# LPC18xx register map
File version: 18
Registers are 32-bit, read-write, reset 0x0 unless marked. A register's access mark holds for its fields unless they carry their own. Offsets are from the block's base; [hi:lo] are bit positions; {n}, {i} and the like mark numbered series; 'fields as' and 'values as' point back to an identical list.

## MCPWM — Product name title=UM10430 Chapter title=LPC18xx Motor Control PWM (MOTOCONPWM) Modification date=1/14/2011 Major revision=0 Minor revision=7
Base 0x400A0000
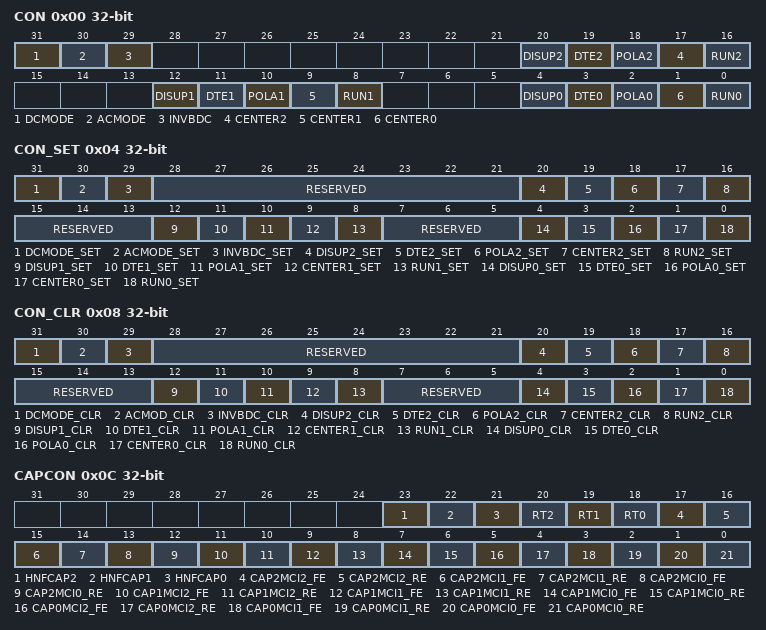
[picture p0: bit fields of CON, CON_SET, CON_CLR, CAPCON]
0x00 CON ro — PWM Control read address
  [31] DCMODE — 3-phase DC mode select (see Section 24.8.6).
    0=3_PHASE_DC_MODE_OFF (3-phase DC mode off: PWM channels are independent (unless bit ACMODE = 1)); 1=3_PHASE_DC_MODE_ON_ (3-phase DC mode on: The internal MCOA0 output is routed through the CP register (i.e. a mask) register to all six PWM outputs.)
  [30] ACMODE — 3-phase AC mode select (see Section 24.8.7).
    0=3_PHASE_AC_MODE_OFF (3-phase AC-mode off: Each PWM channel uses its own timer-counter and period register.); 1=3_PHASE_AC_MODE_ON_ (3-phase AC-mode on: All PWM channels use the timer-counter and period register of channel 0.)
  [29] INVBDC — Controls the polarity of the MCOB outputs for all 3 channels. This bit is typically set to 1 only in 3-phase DC mode.
    0=OPPOSITE (The MCOB outputs have opposite polarity from the MCOA outputs (aside from dead time).); 1=SAME (The MCOB outputs have the same basic polarity as the MCOA outputs. (see Section 24.8.6))
  [20] DISUP2 — Enable/disable updates of functional registers for channel 2 (see Section 24.8.2).
    0=UPDATE (Functional registers are updated from the write registers at the end of each PWM cycle.); 1=NOUPDATE (Functional registers remain the same as long as the timer is running.)
  [19] DTE2 — Controls the dead-time feature for channel 1.
    0=DEAD_TIME_DISABLED_; 1=DEAD_TIME_ENABLED_
  [18] POLA2 — Selects polarity of the MCOA2 and MCOB2 pins.
    0=PASSIVE_STATE_IS_LOW (Passive state is LOW, active state is HIGH.); 1=PASSIVE_STATE_IS_HIG (Passive state is HIGH, active state is LOW.)
  [17] CENTER2 — Edge/center aligned operation for channel 2.
    0=EDGE_ALIGNED_; 1=CENTER_ALIGNED_
  [16] RUN2 — Stops/starts timer channel 2.
    0=STOP_; 1=RUN_
  [12] DISUP1 — Enable/disable updates of functional registers for channel 1 (see Section 24.8.2).
    values as DISUP2
  [11] DTE1 — Controls the dead-time feature for channel 1.
    0=DEAD_TIME_DISABLED_; 1=DEAD_TIME_ENABLED_
  [10] POLA1 — Selects polarity of the MCOA1 and MCOB1 pins.
    values as POLA2
  [9] CENTER1 — Edge/center aligned operation for channel 1.
    0=EDGE_ALIGNED_; 1=CENTER_ALIGNED_
  [8] RUN1 — Stops/starts timer channel 1.
    0=STOP_; 1=RUN_
  [4] DISUP0 — Enable/disable updates of functional registers for channel 0 (see Section 24.8.2).
    values as DISUP2
  [3] DTE0 — Controls the dead-time feature for channel 0.
    0=DEAD_TIME_DISABLED_; 1=DEAD_TIME_ENABLED_
  [2] POLA0 — Selects polarity of the MCOA0 and MCOB0 pins.
    values as POLA2
  [1] CENTER0 — Edge/center aligned operation for channel 0.
    0=EDGE_ALIGNED_; 1=CENTER_ALIGNED_
  [0] RUN0 — Stops/starts timer channel 0.
    0=STOP_; 1=RUN_
0x04 CON_SET wo reset not defined — PWM Control set address
  [31] DCMODE_SET — Writing a one sets the corresponding bit in the CON register.
  [30] ACMODE_SET — Writing a one sets the corresponding bit in the CON register.
  [29] INVBDC_SET — Writing a one sets the corresponding bit in the CON register.
  [28:21] RESERVED — Writing a one sets the corresponding bit in the CON register.
  [20] DISUP2_SET — Writing a one sets the corresponding bit in the CON register.
  [19] DTE2_SET — Writing a one sets the corresponding bit in the CON register.
  [18] POLA2_SET — Writing a one sets the corresponding bit in the CON register.
  [17] CENTER2_SET — Writing a one sets the corresponding bit in the CON register.
  [16] RUN2_SET — Writing a one sets the corresponding bit in the CON register.
  [15:13] RESERVED — Writing a one sets the corresponding bit in the CON register.
  [12] DISUP1_SET — Writing a one sets the corresponding bit in the CON register.
  [11] DTE1_SET — Writing a one sets the corresponding bit in the CON register.
  [10] POLA1_SET — Writing a one sets the corresponding bit in the CON register.
  [9] CENTER1_SET — Writing a one sets the corresponding bit in the CON register.
  [8] RUN1_SET — Writing a one sets the corresponding bit in the CON register.
  [7:5] RESERVED — Writing a one sets the corresponding bit in the CON register.
  [4] DISUP0_SET — Writing a one sets the corresponding bit in the CON register.
  [3] DTE0_SET — Writing a one sets the corresponding bit in the CON register.
  [2] POLA0_SET — Writing a one sets the corresponding bit in the CON register.
  [1] CENTER0_SET — Writing a one sets the corresponding bit in the CON register.
  [0] RUN0_SET — Writing a one sets the corresponding bit in the CON register.
0x08 CON_CLR wo reset not defined — PWM Control clear address
  [31] DCMODE_CLR — Writing a one clears the corresponding bit in the CON register.
  [30] ACMOD_CLR — Writing a one clears the corresponding bit in the CON register.
  [29] INVBDC_CLR — Writing a one clears the corresponding bit in the CON register.
  [28:21] RESERVED — Writing a one clears the corresponding bit in the CON register.
  [20] DISUP2_CLR — Writing a one clears the corresponding bit in the CON register.
  [19] DTE2_CLR — Writing a one clears the corresponding bit in the CON register.
  [18] POLA2_CLR — Writing a one clears the corresponding bit in the CON register.
  [17] CENTER2_CLR — Writing a one clears the corresponding bit in the CON register.
  [16] RUN2_CLR — Writing a one clears the corresponding bit in the CON register.
  [15:13] RESERVED — Writing a one clears the corresponding bit in the CON register.
  [12] DISUP1_CLR — Writing a one clears the corresponding bit in the CON register.
  [11] DTE1_CLR — Writing a one clears the corresponding bit in the CON register.
  [10] POLA1_CLR — Writing a one clears the corresponding bit in the CON register.
  [9] CENTER1_CLR — Writing a one clears the corresponding bit in the CON register.
  [8] RUN1_CLR — Writing a one clears the corresponding bit in the CON register.
  [7:5] RESERVED — Writing a one clears the corresponding bit in the CON register.
  [4] DISUP0_CLR — Writing a one clears the corresponding bit in the CON register.
  [3] DTE0_CLR — Writing a one clears the corresponding bit in the CON register.
  [2] POLA0_CLR — Writing a one clears the corresponding bit in the CON register.
  [1] CENTER0_CLR — Writing a one clears the corresponding bit in the CON register.
  [0] RUN0_CLR — Writing a one clears the corresponding bit in the CON register.
0x0C CAPCON ro — Capture Control read address
  [23] HNFCAP2 — Hardware noise filter: if this bit is 1, channel 2 capture events are delayed as described in Section 24.8.4.
  [22] HNFCAP1 — Hardware noise filter: if this bit is 1, channel 1 capture events are delayed as described in Section 24.8.4.
  [21] HNFCAP0 — Hardware noise filter: if this bit is 1, channel 0 capture events are delayed as described in Section 24.8.4.
  [20] RT2 — If this bit is 1, TC2 is reset by a channel 2 capture event.
  [19] RT1 — If this bit is 1, TC1 is reset by a channel 1 capture event.
  [18] RT0 — If this bit is 1, TC0 is reset by a channel 0 capture event.
  [17] CAP2MCI2_FE — A 1 in this bit enables a channel 2 capture event on a falling edge on MCI2.
  [16] CAP2MCI2_RE — A 1 in this bit enables a channel 2 capture event on a rising edge on MCI2.
  [15] CAP2MCI1_FE — A 1 in this bit enables a channel 2 capture event on a falling edge on MCI1.
  [14] CAP2MCI1_RE — A 1 in this bit enables a channel 2 capture event on a rising edge on MCI1.
  [13] CAP2MCI0_FE — A 1 in this bit enables a channel 2 capture event on a falling edge on MCI0.
  [12] CAP2MCI0_RE — A 1 in this bit enables a channel 2 capture event on a rising edge on MCI0.
  [11] CAP1MCI2_FE — A 1 in this bit enables a channel 1 capture event on a falling edge on MCI2.
  [10] CAP1MCI2_RE — A 1 in this bit enables a channel 1 capture event on a rising edge on MCI2.
  [9] CAP1MCI1_FE — A 1 in this bit enables a channel 1 capture event on a falling edge on MCI1.
  [8] CAP1MCI1_RE — A 1 in this bit enables a channel 1 capture event on a rising edge on MCI1.
  [7] CAP1MCI0_FE — A 1 in this bit enables a channel 1 capture event on a falling edge on MCI0.
  [6] CAP1MCI0_RE — A 1 in this bit enables a channel 1 capture event on a rising edge on MCI0.
  [5] CAP0MCI2_FE — A 1 in this bit enables a channel 0 capture event on a falling edge on MCI2.
  [4] CAP0MCI2_RE — A 1 in this bit enables a channel 0 capture event on a rising edge on MCI2.
  [3] CAP0MCI1_FE — A 1 in this bit enables a channel 0 capture event on a falling edge on MCI1.
  [2] CAP0MCI1_RE — A 1 in this bit enables a channel 0 capture event on a rising edge on MCI1.
  [1] CAP0MCI0_FE — A 1 in this bit enables a channel 0 capture event on a falling edge on MCI0.
  [0] CAP0MCI0_RE — A 1 in this bit enables a channel 0 capture event on a rising edge on MCI0.
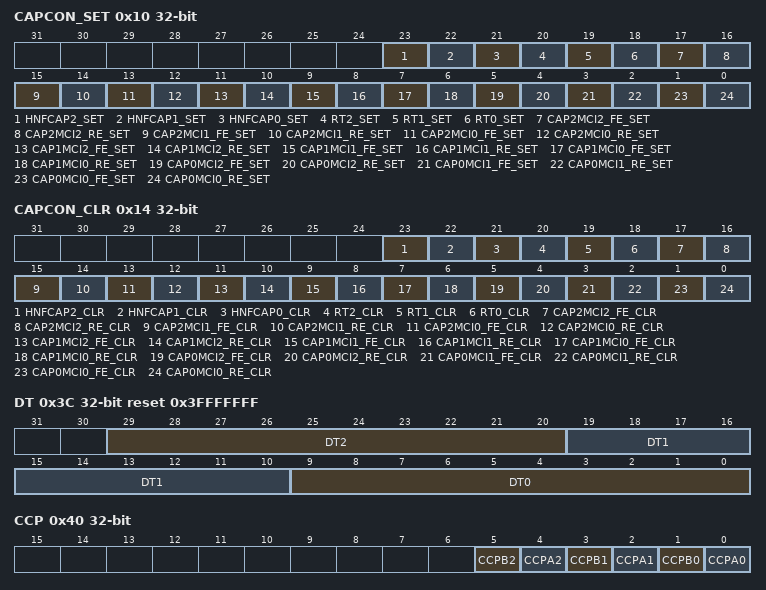
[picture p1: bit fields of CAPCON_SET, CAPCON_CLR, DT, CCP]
0x10 CAPCON_SET wo reset not defined — Capture Control set address
  [23] HNFCAP2_SET — Writing a one sets the corresponding bits in the CAPCON register.
  [22] HNFCAP1_SET — Writing a one sets the corresponding bits in the CAPCON register.
  [21] HNFCAP0_SET — Writing a one sets the corresponding bits in the CAPCON register.
  [20] RT2_SET — Writing a one sets the corresponding bits in the CAPCON register.
  [19] RT1_SET — Writing a one sets the corresponding bits in the CAPCON register.
  [18] RT0_SET — Writing a one sets the corresponding bits in the CAPCON register.
  [17] CAP2MCI2_FE_SET — Writing a one sets the corresponding bits in the CAPCON register.
  [16] CAP2MCI2_RE_SET — Writing a one sets the corresponding bits in the CAPCON register.
  [15] CAP2MCI1_FE_SET — Writing a one sets the corresponding bits in the CAPCON register.
  [14] CAP2MCI1_RE_SET — Writing a one sets the corresponding bits in the CAPCON register.
  [13] CAP2MCI0_FE_SET — Writing a one sets the corresponding bits in the CAPCON register.
  [12] CAP2MCI0_RE_SET — Writing a one sets the corresponding bits in the CAPCON register.
  [11] CAP1MCI2_FE_SET — Writing a one sets the corresponding bits in the CAPCON register.
  [10] CAP1MCI2_RE_SET — Writing a one sets the corresponding bits in the CAPCON register.
  [9] CAP1MCI1_FE_SET — Writing a one sets the corresponding bits in the CAPCON register.
  [8] CAP1MCI1_RE_SET — Writing a one sets the corresponding bits in the CAPCON register.
  [7] CAP1MCI0_FE_SET — Writing a one sets the corresponding bits in the CAPCON register.
  [6] CAP1MCI0_RE_SET — Writing a one sets the corresponding bits in the CAPCON register.
  [5] CAP0MCI2_FE_SET — Writing a one sets the corresponding bits in the CAPCON register.
  [4] CAP0MCI2_RE_SET — Writing a one sets the corresponding bits in the CAPCON register.
  [3] CAP0MCI1_FE_SET — Writing a one sets the corresponding bits in the CAPCON register.
  [2] CAP0MCI1_RE_SET — Writing a one sets the corresponding bits in the CAPCON register.
  [1] CAP0MCI0_FE_SET — Writing a one sets the corresponding bits in the CAPCON register.
  [0] CAP0MCI0_RE_SET — Writing a one sets the corresponding bits in the CAPCON register.
0x14 CAPCON_CLR wo reset not defined — Event Control clear address
  [23] HNFCAP2_CLR — Writing a one clears the corresponding bits in the CAPCON register.
  [22] HNFCAP1_CLR — Writing a one clears the corresponding bits in the CAPCON register.
  [21] HNFCAP0_CLR — Writing a one clears the corresponding bits in the CAPCON register.
  [20] RT2_CLR — Writing a one clears the corresponding bits in the CAPCON register.
  [19] RT1_CLR — Writing a one clears the corresponding bits in the CAPCON register.
  [18] RT0_CLR — Writing a one clears the corresponding bits in the CAPCON register.
  [17] CAP2MCI2_FE_CLR — Writing a one clears the corresponding bits in the CAPCON register.
  [16] CAP2MCI2_RE_CLR — Writing a one clears the corresponding bits in the CAPCON register.
  [15] CAP2MCI1_FE_CLR — Writing a one clears the corresponding bits in the CAPCON register.
  [14] CAP2MCI1_RE_CLR — Writing a one clears the corresponding bits in the CAPCON register.
  [13] CAP2MCI0_FE_CLR — Writing a one clears the corresponding bits in the CAPCON register.
  [12] CAP2MCI0_RE_CLR — Writing a one clears the corresponding bits in the CAPCON register.
  [11] CAP1MCI2_FE_CLR — Writing a one clears the corresponding bits in the CAPCON register.
  [10] CAP1MCI2_RE_CLR — Writing a one clears the corresponding bits in the CAPCON register.
  [9] CAP1MCI1_FE_CLR — Writing a one clears the corresponding bits in the CAPCON register.
  [8] CAP1MCI1_RE_CLR — Writing a one clears the corresponding bits in the CAPCON register.
  [7] CAP1MCI0_FE_CLR — Writing a one clears the corresponding bits in the CAPCON register.
  [6] CAP1MCI0_RE_CLR — Writing a one clears the corresponding bits in the CAPCON register.
  [5] CAP0MCI2_FE_CLR — Writing a one clears the corresponding bits in the CAPCON register.
  [4] CAP0MCI2_RE_CLR — Writing a one clears the corresponding bits in the CAPCON register.
  [3] CAP0MCI1_FE_CLR — Writing a one clears the corresponding bits in the CAPCON register.
  [2] CAP0MCI1_RE_CLR — Writing a one clears the corresponding bits in the CAPCON register.
  [1] CAP0MCI0_FE_CLR — Writing a one clears the corresponding bits in the CAPCON register.
  [0] CAP0MCI0_RE_CLR — Writing a one clears the corresponding bits in the CAPCON register.
{0x18+4i} TC{i} (i=0..2) — Timer Counter register
  [31:0] MCTC — Timer/Counter value.
{0x24+4i} LIM{i} (i=0..2) — Limit register
  [31:0] MCLIM — Limit value.
{0x30+4i} MAT{i} (i=0..2) — Match register
  [31:0] MCMAT — Match value.
0x3C DT reset 0x3FFFFFFF — Dead time register
  [29:20] DT2 — Dead time for channel 2.[2]
  [19:10] DT1 — Dead time for channel 1.[2]
  [9:0] DT0 — Dead time for channel 0.[1]
0x40 CCP — Communication Pattern register
  [5] CCPB2 — Communication pattern output B, channel 2.
    0=MCOB2_PASSIVE_; 1=MCOB2_TRACKS_INTERNA (MCOB2 tracks internal MCOA0.)
  [4] CCPA2 — Communication pattern output A, channel 2.
    0=MCOA2_PASSIVE_; 1=MCOA2_TRACKS_INTERNA (MCOA2 tracks internal MCOA0.)
  [3] CCPB1 — Communication pattern output B, channel 1.
    0=MCOB1_PASSIVE_; 1=MCOB1_TRACKS_INTERNA (MCOB1 tracks internal MCOA0.)
  [2] CCPA1 — Communication pattern output A, channel 1.
    0=MCOA1_PASSIVE_; 1=MCOA1_TRACKS_INTERNA (MCOA1 tracks internal MCOA0.)
  [1] CCPB0 — Communication pattern output B, channel 0.
    0=MCOB0_PASSIVE_; 1=MCOB0_TRACKS_INTERNA (MCOB0 tracks internal MCOA0.)
  [0] CCPA0 — Communication pattern output A, channel 0.
    0=MCOA0_PASSIVE_; 1=INTERNAL_MCOA0_
{0x44+4i} CAP{i} (i=0..2) ro — Capture register
  [31:0] CAP — Current TC value at a capture event.
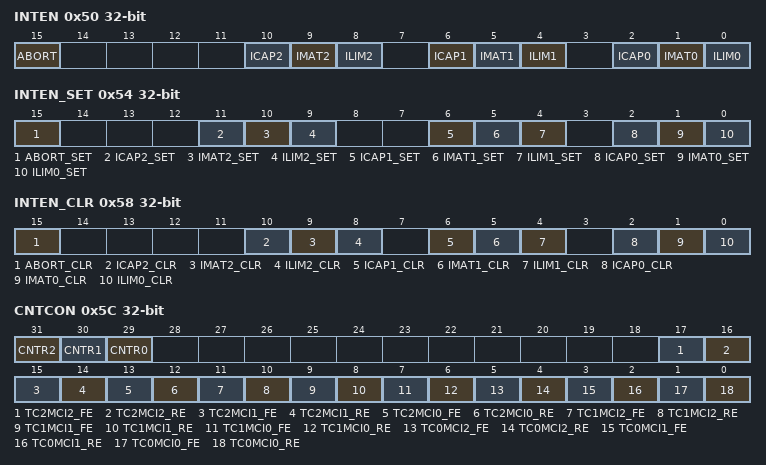
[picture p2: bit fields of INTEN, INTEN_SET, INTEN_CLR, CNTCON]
0x50 INTEN ro — Interrupt Enable read address
  [all] fields
    0=INTERRUPT_DISABLED_; 1=INTERRUPT_ENABLED_
  [15] ABORT — Fast abort interrupt.
  [10] ICAP2 — Capture interrupt for channel 2.
  [9] IMAT2 — Match interrupt for channel 2.
  [8] ILIM2 — Limit interrupt for channel 2.
  [6] ICAP1 — Capture interrupt for channel 1.
  [5] IMAT1 — Match interrupt for channel 1.
  [4] ILIM1 — Limit interrupt for channel 1.
  [2] ICAP0 — Capture interrupt for channel 0.
  [1] IMAT0 — Match interrupt for channel 0.
  [0] ILIM0 — Limit interrupt for channel 0.
0x54 INTEN_SET wo reset not defined — Interrupt Enable set address
  [15] ABORT_SET — Writing a one sets the corresponding bit in INTEN, thus enabling the interrupt.
  [11] ICAP2_SET — Writing a one sets the corresponding bit in INTEN, thus enabling the interrupt.
  [10] IMAT2_SET — Writing a one sets the corresponding bit in INTEN, thus enabling the interrupt.
  [9] ILIM2_SET — Writing a one sets the corresponding bit in INTEN, thus enabling the interrupt.
  [6] ICAP1_SET — Writing a one sets the corresponding bit in INTEN, thus enabling the interrupt.
  [5] IMAT1_SET — Writing a one sets the corresponding bit in INTEN, thus enabling the interrupt.
  [4] ILIM1_SET — Writing a one sets the corresponding bit in INTEN, thus enabling the interrupt.
  [2] ICAP0_SET — Writing a one sets the corresponding bit in INTEN, thus enabling the interrupt.
  [1] IMAT0_SET — Writing a one sets the corresponding bit in INTEN, thus enabling the interrupt.
  [0] ILIM0_SET — Writing a one sets the corresponding bit in INTEN, thus enabling the interrupt.
0x58 INTEN_CLR wo reset not defined — Interrupt Enable clear address
  [15] ABORT_CLR — Writing a one clears the corresponding bit in INTEN, thus disabling the interrupt.
  [10] ICAP2_CLR — Writing a one clears the corresponding bit in INTEN, thus disabling the interrupt.
  [9] IMAT2_CLR — Writing a one clears the corresponding bit in INTEN, thus disabling the interrupt.
  [8] ILIM2_CLR — Writing a one clears the corresponding bit in INTEN, thus disabling the interrupt.
  [6] ICAP1_CLR — Writing a one clears the corresponding bit in INTEN, thus disabling the interrupt.
  [5] IMAT1_CLR — Writing a one clears the corresponding bit in INTEN, thus disabling the interrupt.
  [4] ILIM1_CLR — Writing a one clears the corresponding bit in INTEN, thus disabling the interrupt.
  [2] ICAP0_CLR — Writing a one clears the corresponding bit in INTEN, thus disabling the interrupt.
  [1] IMAT0_CLR — Writing a one clears the corresponding bit in INTEN, thus disabling the interrupt.
  [0] ILIM0_CLR — Writing a one clears the corresponding bit in INTEN, thus disabling the interrupt.
0x5C CNTCON ro — Count Control read address
  [31] CNTR2 — Channel 2 counter/timer mode.
    0=CHANNEL_2_IS_IN_TIME (Channel 2 is in timer mode.); 1=CHANNEL_2_IS_IN_COUN (Channel 2 is in counter mode.)
  [30] CNTR1 — Channel 1 counter/timer mode.
    0=CHANNEL_1_IS_IN_TIME (Channel 1 is in timer mode.); 1=CHANNEL_1_IS_IN_COUN (Channel 1 is in counter mode.)
  [29] CNTR0 — Channel 0 counter/timer mode.
    0=CHANNEL_0_IS_IN_TIME (Channel 0 is in timer mode.); 1=CHANNEL_0_IS_IN_COUN (Channel 0 is in counter mode.)
  [17] TC2MCI2_FE — Counter 2 falling edge mode, channel 2.
    0=A_FALLING_EDGE_ON_MC (A falling edge on MCI2 does not affect counter 2.); 1=IF_MODE2_IS_1,_COUNT (If MODE2 is 1, counter 2 advances on a falling edge on MCI2.)
  [16] TC2MCI2_RE — Counter 2 rising edge mode, channel 2.
    0=A_RISING_EDGE_ON_MCI (A rising edge on MCI2 does not affect counter 2.); 1=IF_MODE2_IS_1,_COUNT (If MODE2 is 1, counter 2 advances on a rising edge on MCI2.)
  [15] TC2MCI1_FE — Counter 2 falling edge mode, channel 1.
    0=A_FALLING_EDGE_ON_MC (A falling edge on MCI1 does not affect counter 2.); 1=IF_MODE2_IS_1,_COUNT (If MODE2 is 1, counter 2 advances on a falling edge on MCI1.)
  [14] TC2MCI1_RE — Counter 2 rising edge mode, channel 1.
    0=A_RISING_EDGE_ON_MCI (A rising edge on MCI1 does not affect counter 2.); 1=IF_MODE2_IS_1,_COUNT (If MODE2 is 1, counter 2 advances on a rising edge on MCI1.)
  [13] TC2MCI0_FE — Counter 2 falling edge mode, channel 0.
    0=A_FALLING_EDGE_ON_MC (A falling edge on MCI0 does not affect counter 2.); 1=IF_MODE2_IS_1,_COUNT (If MODE2 is 1, counter 2 advances on a falling edge on MCI0.)
  [12] TC2MCI0_RE — Counter 2 rising edge mode, channel 0.
    0=A_RISING_EDGE_ON_MCI (A rising edge on MCI0 does not affect counter 2.); 1=IF_MODE2_IS_1,_COUNT (If MODE2 is 1, counter 2 advances on a rising edge on MCI0.)
  [11] TC1MCI2_FE — Counter 1 falling edge mode, channel 2.
    0=A_FALLING_EDGE_ON_MC (A falling edge on MCI2 does not affect counter 1.); 1=IF_MODE1_IS_1,_COUNT (If MODE1 is 1, counter 1 advances on a falling edge on MCI2.)
  [10] TC1MCI2_RE — Counter 1 rising edge mode, channel 2.
    0=A_RISING_EDGE_ON_MCI (A rising edge on MCI2 does not affect counter 1.); 1=IF_MODE1_IS_1,_COUNT (If MODE1 is 1, counter 1 advances on a rising edge on MCI2.)
  [9] TC1MCI1_FE — Counter 1 falling edge mode, channel 1.
    0=A_FALLING_EDGE_ON_MC (A falling edge on MCI0 does not affect counter 1.); 1=IF_MODE1_IS_1,_COUNT (If MODE1 is 1, counter 1 advances on a falling edge on MCI1.)
  [8] TC1MCI1_RE — Counter 1 rising edge mode, channel 1.
    0=A_RISING_EDGE_ON_MCI (A rising edge on MCI1 does not affect counter 1.); 1=IF_MODE1_IS_1,_COUNT (If MODE1 is 1, counter 1 advances on a rising edge on MCI1.)
  [7] TC1MCI0_FE — Counter 1 falling edge mode, channel 0.
    0=A_FALLING_EDGE_ON_MC (A falling edge on MCI0 does not affect counter 1.); 1=IF_MODE1_IS_1,_COUNT (If MODE1 is 1, counter 1 advances on a falling edge on MCI0.)
  [6] TC1MCI0_RE — Counter 1 rising edge mode, channel 0.
    0=A_RISING_EDGE_ON_MCI (A rising edge on MCI0 does not affect counter 1.); 1=IF_MODE1_IS_1,_COUNT (If MODE1 is 1, counter 1 advances on a rising edge on MCI0.)
  [5] TC0MCI2_FE — Counter 0 falling edge mode, channel 2.
    0=A_FALLING_EDGE_ON_MC (A falling edge on MCI0 does not affect counter 0.); 1=IF_MODE0_IS_1,_COUNT (If MODE0 is 1, counter 0 advances on a falling edge on MCI2.)
  [4] TC0MCI2_RE — Counter 0 rising edge mode, channel 2.
    0=A_RISING_EDGE_ON_MCI (A rising edge on MCI0 does not affect counter 0.); 1=IF_MODE0_IS_1,_COUNT (If MODE0 is 1, counter 0 advances on a rising edge on MCI2.)
  [3] TC0MCI1_FE — Counter 0 falling edge mode, channel 1.
    0=A_FALLING_EDGE_ON_MC (A falling edge on MCI1 does not affect counter 0.); 1=IF_MODE0_IS_1,_COUNT (If MODE0 is 1, counter 0 advances on a falling edge on MCI1.)
  [2] TC0MCI1_RE — Counter 0 rising edge mode, channel 1.
    0=A_RISING_EDGE_ON_MCI (A rising edge on MCI1 does not affect counter 0.); 1=IF_MODE0_IS_1,_COUNT (If MODE0 is 1, counter 0 advances on a rising edge on MCI1.)
  [1] TC0MCI0_FE — Counter 0 falling edge mode, channel 0.
    0=A_FALLING_EDGE_ON_MC (A falling edge on MCI0 does not affect counter 0.); 1=IF_MODE0_IS_1,_COUNT (If MODE0 is 1, counter 0 advances on a falling edge on MCI0.)
  [0] TC0MCI0_RE — Counter 0 rising edge mode, channel 0.
    0=A_RISING_EDGE_ON_MCI (A rising edge on MCI0 does not affect counter 0.); 1=IF_MODE0_IS_1,_COUNT (If MODE0 is 1, counter 0 advances on a rising edge on MCI0.)
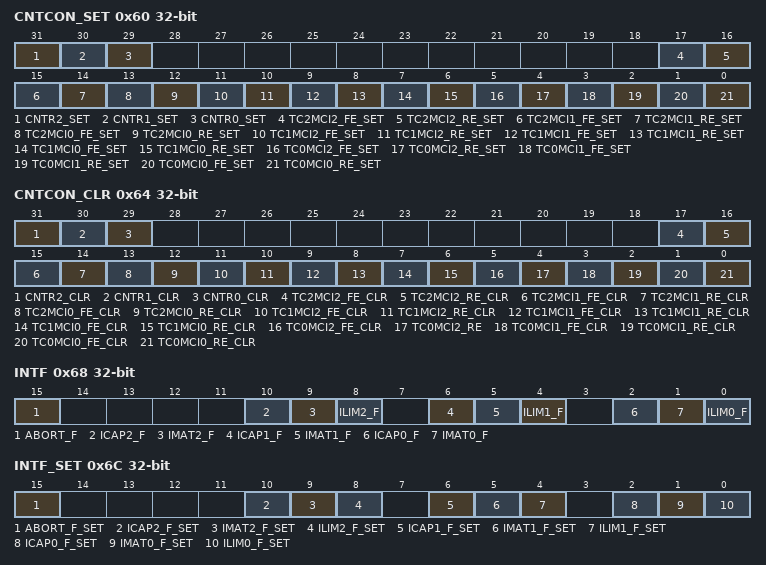
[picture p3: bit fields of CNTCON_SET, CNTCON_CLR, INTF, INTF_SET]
0x60 CNTCON_SET wo reset not defined — Count Control set address
  [31] CNTR2_SET — Writing a one sets the corresponding bit in the CNTCON register.
  [30] CNTR1_SET — Writing a one sets the corresponding bit in the CNTCON register.
  [29] CNTR0_SET — Writing a one sets the corresponding bit in the CNTCON register.
  [17] TC2MCI2_FE_SET — Writing a one sets the corresponding bit in the CNTCON register.
  [16] TC2MCI2_RE_SET — Writing a one sets the corresponding bit in the CNTCON register.
  [15] TC2MCI1_FE_SET — Writing a one sets the corresponding bit in the CNTCON register.
  [14] TC2MCI1_RE_SET — Writing a one sets the corresponding bit in the CNTCON register.
  [13] TC2MCI0_FE_SET — Writing a one sets the corresponding bit in the CNTCON register.
  [12] TC2MCI0_RE_SET — Writing a one sets the corresponding bit in the CNTCON register.
  [11] TC1MCI2_FE_SET — Writing a one sets the corresponding bit in the CNTCON register.
  [10] TC1MCI2_RE_SET — Writing a one sets the corresponding bit in the CNTCON register.
  [9] TC1MCI1_FE_SET — Writing a one sets the corresponding bit in the CNTCON register.
  [8] TC1MCI1_RE_SET — Writing a one sets the corresponding bit in the CNTCON register.
  [7] TC1MCI0_FE_SET — Writing a one sets the corresponding bit in the CNTCON register.
  [6] TC1MCI0_RE_SET — Writing a one sets the corresponding bit in the CNTCON register.
  [5] TC0MCI2_FE_SET — Writing a one sets the corresponding bit in the CNTCON register.
  [4] TC0MCI2_RE_SET — Writing a one sets the corresponding bit in the CNTCON register.
  [3] TC0MCI1_FE_SET — Writing a one sets the corresponding bit in the CNTCON register.
  [2] TC0MCI1_RE_SET — Writing a one sets the corresponding bit in the CNTCON register.
  [1] TC0MCI0_FE_SET — Writing a one sets the corresponding bit in the CNTCON register.
  [0] TC0MCI0_RE_SET — Writing a one sets the corresponding bit in the CNTCON register.
0x64 CNTCON_CLR wo reset not defined — Count Control clear address
  [31] CNTR2_CLR — Writing a one clears the corresponding bit in the CNTCON register.
  [30] CNTR1_CLR — Writing a one clears the corresponding bit in the CNTCON register.
  [29] CNTR0_CLR — Writing a one clears the corresponding bit in the CNTCON register.
  [17] TC2MCI2_FE_CLR — Writing a one clears the corresponding bit in the CNTCON register.
  [16] TC2MCI2_RE_CLR — Writing a one clears the corresponding bit in the CNTCON register.
  [15] TC2MCI1_FE_CLR — Writing a one clears the corresponding bit in the CNTCON register.
  [14] TC2MCI1_RE_CLR — Writing a one clears the corresponding bit in the CNTCON register.
  [13] TC2MCI0_FE_CLR — Writing a one clears the corresponding bit in the CNTCON register.
  [12] TC2MCI0_RE_CLR — Writing a one clears the corresponding bit in the CNTCON register.
  [11] TC1MCI2_FE_CLR — Writing a one clears the corresponding bit in the CNTCON register.
  [10] TC1MCI2_RE_CLR — Writing a one clears the corresponding bit in the CNTCON register.
  [9] TC1MCI1_FE_CLR — Writing a one clears the corresponding bit in the CNTCON register.
  [8] TC1MCI1_RE_CLR — Writing a one clears the corresponding bit in the CNTCON register.
  [7] TC1MCI0_FE_CLR — Writing a one clears the corresponding bit in the CNTCON register.
  [6] TC1MCI0_RE_CLR — Writing a one clears the corresponding bit in the CNTCON register.
  [5] TC0MCI2_FE_CLR — Writing a one clears the corresponding bit in the CNTCON register.
  [4] TC0MCI2_RE — Writing a one clears the corresponding bit in the CNTCON register.
  [3] TC0MCI1_FE_CLR — Writing a one clears the corresponding bit in the CNTCON register.
  [2] TC0MCI1_RE_CLR — Writing a one clears the corresponding bit in the CNTCON register.
  [1] TC0MCI0_FE_CLR — Writing a one clears the corresponding bit in the CNTCON register.
  [0] TC0MCI0_RE_CLR — Writing a one clears the corresponding bit in the CNTCON register.
0x68 INTF ro — Interrupt flags read address
  [all] fields
    0=THIS_INTERRUPT_SOURC (This interrupt source is not contributing to the MCPWM interrupt request.); 1=IF_THE_CORRESPONDING (If the corresponding bit in INTEN is 1, the MCPWM module is asserting its interrupt request to the Interrupt Controller.)
  [15] ABORT_F — Fast abort interrupt flag.
  [10] ICAP2_F — Capture interrupt flag for channel 2.
  [9] IMAT2_F — Match interrupt flag for channel 2.
  [8] ILIM2_F — Limit interrupt flag for channel 2.
  [6] ICAP1_F — Capture interrupt flag for channel 1.
  [5] IMAT1_F — Match interrupt flag for channel 1.
  [4] ILIM1_F — Limit interrupt flag for channel 1.
  [2] ICAP0_F — Capture interrupt flag for channel 0.
  [1] IMAT0_F — Match interrupt flag for channel 0.
  [0] ILIM0_F — Limit interrupt flag for channel 0.
0x6C INTF_SET wo reset not defined — Interrupt flags set address
  [15] ABORT_F_SET — Writing a one sets the corresponding bit in the INTF register, thus possibly simulating hardware interrupt.
  [10] ICAP2_F_SET — Writing a one sets the corresponding bit in the INTF register, thus possibly simulating hardware interrupt.
  [9] IMAT2_F_SET — Writing a one sets the corresponding bit in the INTF register, thus possibly simulating hardware interrupt.
  [8] ILIM2_F_SET — Writing a one sets the corresponding bit in the INTF register, thus possibly simulating hardware interrupt.
  [6] ICAP1_F_SET — Writing a one sets the corresponding bit in the INTF register, thus possibly simulating hardware interrupt.
  [5] IMAT1_F_SET — Writing a one sets the corresponding bit in the INTF register, thus possibly simulating hardware interrupt.
  [4] ILIM1_F_SET — Writing a one sets the corresponding bit in the INTF register, thus possibly simulating hardware interrupt.
  [2] ICAP0_F_SET — Writing a one sets the corresponding bit in the INTF register, thus possibly simulating hardware interrupt.
  [1] IMAT0_F_SET — Writing a one sets the corresponding bit in the INTF register, thus possibly simulating hardware interrupt.
  [0] ILIM0_F_SET — Writing a one sets the corresponding bit in the INTF register, thus possibly simulating hardware interrupt.
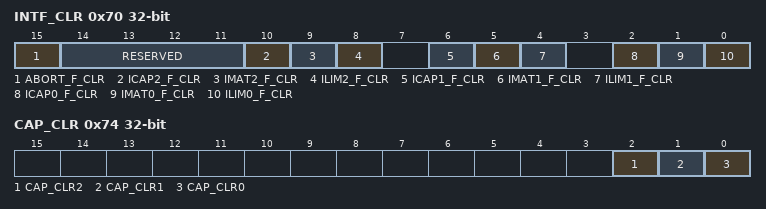
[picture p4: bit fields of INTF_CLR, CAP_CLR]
0x70 INTF_CLR wo reset not defined — Interrupt flags clear address
  [15] ABORT_F_CLR — Writing a one clears the corresponding bit in INTEN, thus disabling the interrupt.
  [14:11] RESERVED — Writing a one clears the corresponding bit in INTEN, thus disabling the interrupt.
  [10] ICAP2_F_CLR — Writing a one clears the corresponding bit in INTEN, thus disabling the interrupt.
  [9] IMAT2_F_CLR — Writing a one clears the corresponding bit in INTEN, thus disabling the interrupt.
  [8] ILIM2_F_CLR — Writing a one clears the corresponding bit in INTEN, thus disabling the interrupt.
  [6] ICAP1_F_CLR — Writing a one clears the corresponding bit in INTEN, thus disabling the interrupt.
  [5] IMAT1_F_CLR — Writing a one clears the corresponding bit in INTEN, thus disabling the interrupt.
  [4] ILIM1_F_CLR — Writing a one clears the corresponding bit in INTEN, thus disabling the interrupt.
  [2] ICAP0_F_CLR — Writing a one clears the corresponding bit in INTEN, thus disabling the interrupt.
  [1] IMAT0_F_CLR — Writing a one clears the corresponding bit in INTEN, thus disabling the interrupt.
  [0] ILIM0_F_CLR — Writing a one clears the corresponding bit in the INTF register, thus clearing the corresponding interrupt request.
0x74 CAP_CLR wo reset not defined — Capture clear address
  [2] CAP_CLR2 — Writing a 1 to this bit clears the CAP2 register.
  [1] CAP_CLR1 — Writing a 1 to this bit clears the CAP1 register.
  [0] CAP_CLR0 — Writing a 1 to this bit clears the CAP0 register.
